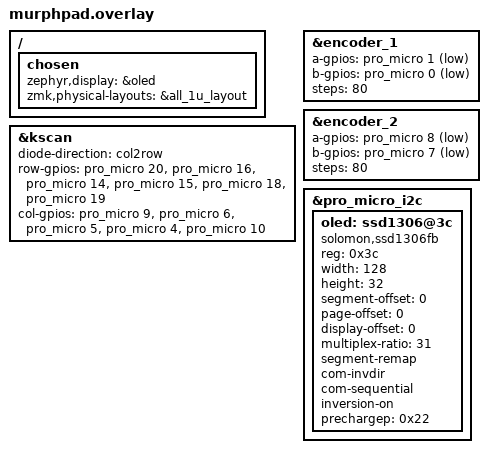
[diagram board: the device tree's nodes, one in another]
/*
 * MurphPad custom overlay
 * Nice!Nano v2 + 23 keys + 2 encoders + 0.91" OLED
 */

#include <dt-bindings/zmk/matrix_transform.h>
#include "murphpad-layout.dtsi"

/ {
    chosen {
        zephyr,display = &oled;
        zmk,physical-layouts = &all_1u_layout;
    };
};

/* ================= MATRIX OVERRIDE ================= */

&kscan {
    diode-direction = "col2row";

    row-gpios
        = <&pro_micro 20 (GPIO_ACTIVE_HIGH | GPIO_PULL_DOWN)>
        , <&pro_micro 16 (GPIO_ACTIVE_HIGH | GPIO_PULL_DOWN)>
        , <&pro_micro 14 (GPIO_ACTIVE_HIGH | GPIO_PULL_DOWN)>
        , <&pro_micro 15 (GPIO_ACTIVE_HIGH | GPIO_PULL_DOWN)>
        , <&pro_micro 18 (GPIO_ACTIVE_HIGH | GPIO_PULL_DOWN)>
        , <&pro_micro 19 (GPIO_ACTIVE_HIGH | GPIO_PULL_DOWN)>
        ;

    col-gpios
        = <&pro_micro 9  GPIO_ACTIVE_HIGH>
        , <&pro_micro 6  GPIO_ACTIVE_HIGH>
        , <&pro_micro 5  GPIO_ACTIVE_HIGH>
        , <&pro_micro 4  GPIO_ACTIVE_HIGH>
        , <&pro_micro 10 GPIO_ACTIVE_HIGH>
        ;
};

/* ================= ENCODERS ================= */

/* Encoder 1 */
&encoder_1 {
    a-gpios = <&pro_micro 1 (GPIO_ACTIVE_LOW | GPIO_PULL_UP)>;
    b-gpios = <&pro_micro 0 (GPIO_ACTIVE_LOW | GPIO_PULL_UP)>;
    steps = <80>;
    status = "okay";
};

/* Encoder 2 */
&encoder_2 {
    a-gpios = <&pro_micro 8 (GPIO_ACTIVE_LOW | GPIO_PULL_UP)>;
    b-gpios = <&pro_micro 7 (GPIO_ACTIVE_LOW | GPIO_PULL_UP)>;
    steps = <80>;
    status = "okay";
};

/* ================= OLED ================= */

&pro_micro_i2c {
    status = "okay";

    oled: ssd1306@3c {
        compatible = "solomon,ssd1306fb";
        reg = <0x3c>;
        width = <128>;
        height = <32>;
        segment-offset = <0>;
        page-offset = <0>;
        display-offset = <0>;
        multiplex-ratio = <31>;
        segment-remap;
        com-invdir;
        com-sequential;
        inversion-on;
        prechargep = <0x22>;
    };
};
